# STM32H73x register map
File version: 1.0
CPU: CM7 r0p1, little endian, MPU, FPU, 4 interrupt priority bits
Registers are 32-bit, read-write, reset 0x0 unless marked. A register's access mark holds for its fields unless they carry their own. Offsets are from the block's base; [hi:lo] are bit positions; {n}, {i} and the like mark numbered series.

## DCMI — Digital camera interface
Base 0x48020000
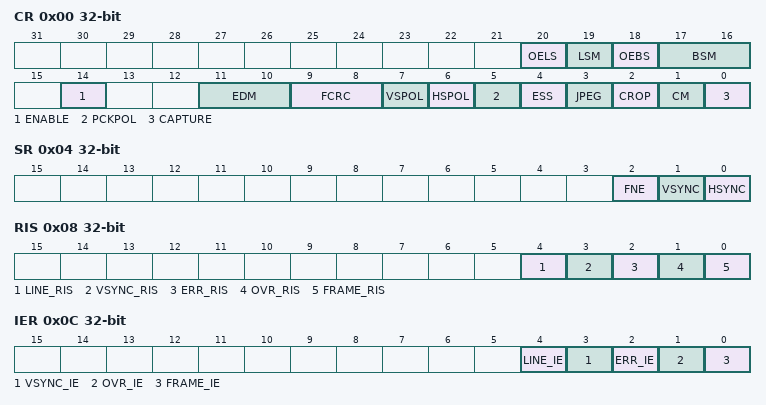
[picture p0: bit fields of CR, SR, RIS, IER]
0x00 CR — control register 1
  [20] OELS — Odd/Even Line Select (Line Select Start)
  [19] LSM — Line Select mode
  [18] OEBS — Odd/Even Byte Select (Byte Select Start)
  [17:16] BSM — Byte Select mode
  [14] ENABLE — DCMI enable
  [11:10] EDM — Extended data mode
  [9:8] FCRC — Frame capture rate control
  [7] VSPOL — Vertical synchronization polarity
  [6] HSPOL — Horizontal synchronization polarity
  [5] PCKPOL — Pixel clock polarity
  [4] ESS — Embedded synchronization select
  [3] JPEG — JPEG format
  [2] CROP — Crop feature
  [1] CM — Capture mode
  [0] CAPTURE — Capture enable
0x04 SR ro — status register
  [2] FNE — FIFO not empty
  [1] VSYNC
  [0] HSYNC
0x08 RIS ro — raw interrupt status register
  [4] LINE_RIS — Line raw interrupt status
  [3] VSYNC_RIS — VSYNC raw interrupt status
  [2] ERR_RIS — Synchronization error raw interrupt status
  [1] OVR_RIS — Overrun raw interrupt status
  [0] FRAME_RIS — Capture complete raw interrupt status
0x0C IER — interrupt enable register
  [4] LINE_IE — Line interrupt enable
  [3] VSYNC_IE — VSYNC interrupt enable
  [2] ERR_IE — Synchronization error interrupt enable
  [1] OVR_IE — Overrun interrupt enable
  [0] FRAME_IE — Capture complete interrupt enable
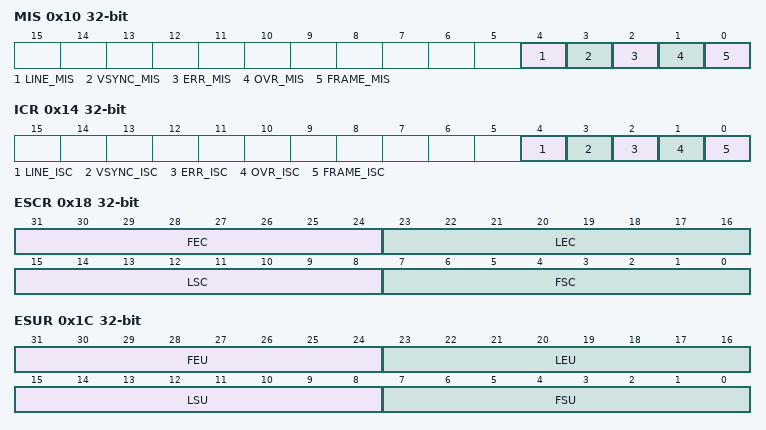
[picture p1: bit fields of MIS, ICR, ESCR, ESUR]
0x10 MIS ro — masked interrupt status register
  [4] LINE_MIS — Line masked interrupt status
  [3] VSYNC_MIS — VSYNC masked interrupt status
  [2] ERR_MIS — Synchronization error masked interrupt status
  [1] OVR_MIS — Overrun masked interrupt status
  [0] FRAME_MIS — Capture complete masked interrupt status
0x14 ICR wo — interrupt clear register
  [4] LINE_ISC — line interrupt status clear
  [3] VSYNC_ISC — Vertical synch interrupt status clear
  [2] ERR_ISC — Synchronization error interrupt status clear
  [1] OVR_ISC — Overrun interrupt status clear
  [0] FRAME_ISC — Capture complete interrupt status clear
0x18 ESCR — embedded synchronization code register
  [31:24] FEC — Frame end delimiter code
  [23:16] LEC — Line end delimiter code
  [15:8] LSC — Line start delimiter code
  [7:0] FSC — Frame start delimiter code
0x1C ESUR — embedded synchronization unmask register
  [31:24] FEU — Frame end delimiter unmask
  [23:16] LEU — Line end delimiter unmask
  [15:8] LSU — Line start delimiter unmask
  [7:0] FSU — Frame start delimiter unmask
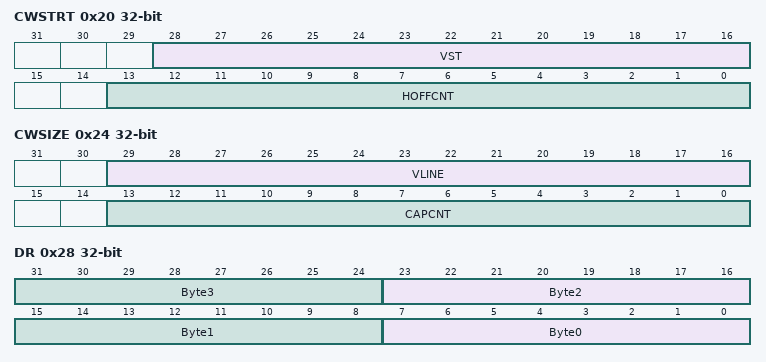
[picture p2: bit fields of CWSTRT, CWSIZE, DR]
0x20 CWSTRT — crop window start
  [28:16] VST — Vertical start line count
  [13:0] HOFFCNT — Horizontal offset count
0x24 CWSIZE — crop window size
  [29:16] VLINE — Vertical line count
  [13:0] CAPCNT — Capture count
0x28 DR ro — data register
  [8n+7:8n] Byte{n} (n=0..3) — Data byte {n}

## OTG1_HS_PWRCLK — USB 1 on the go high speed
Base 0x40040E00
Same registers: OTG2_HS_PWRCLK 0x40080E00
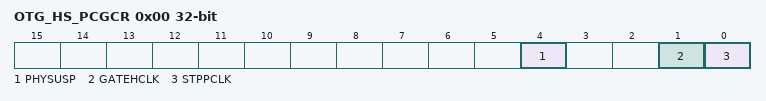
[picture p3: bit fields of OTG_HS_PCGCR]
0x00 OTG_HS_PCGCR — Power and clock gating control register
  [4] PHYSUSP — PHY suspended
  [1] GATEHCLK
  [0] STPPCLK — Stop PHY clock

## TIM16 — General-purpose-timers
Base 0x40014400
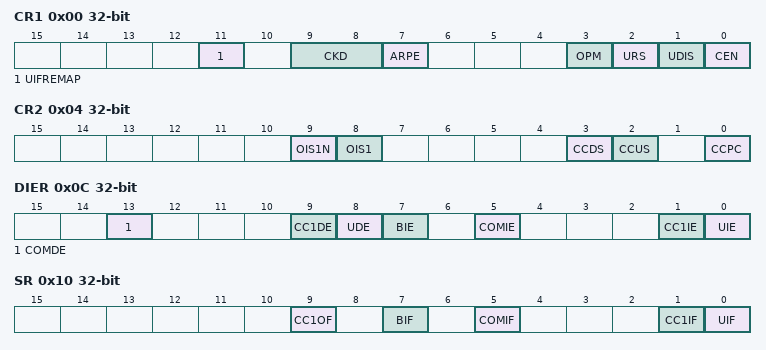
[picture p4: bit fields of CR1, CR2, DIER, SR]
0x00 CR1 — control register 1
  [11] UIFREMAP — UIF status bit remapping
  [9:8] CKD — Clock division
  [7] ARPE — Auto-reload preload enable
  [3] OPM — One-pulse mode
  [2] URS — Update request source
  [1] UDIS — Update disable
  [0] CEN — Counter enable
0x04 CR2 — control register 2
  [9] OIS1N — Output Idle state 1
  [8] OIS1 — Output Idle state 1
  [3] CCDS — Capture/compare DMA selection
  [2] CCUS — Capture/compare control update selection
  [0] CCPC — Capture/compare preloaded control
0x0C DIER — DMA/Interrupt enable register
  [13] COMDE — COM DMA request enable
  [9] CC1DE — Capture/Compare 1 DMA request enable
  [8] UDE — Update DMA request enable
  [7] BIE — Break interrupt enable
  [5] COMIE — COM interrupt enable
  [1] CC1IE — Capture/Compare 1 interrupt enable
  [0] UIE — Update interrupt enable
0x10 SR — status register
  [9] CC1OF — Capture/Compare 1 overcapture flag
  [7] BIF — Break interrupt flag
  [5] COMIF — COM interrupt flag
  [1] CC1IF — Capture/compare 1 interrupt flag
  [0] UIF — Update interrupt flag
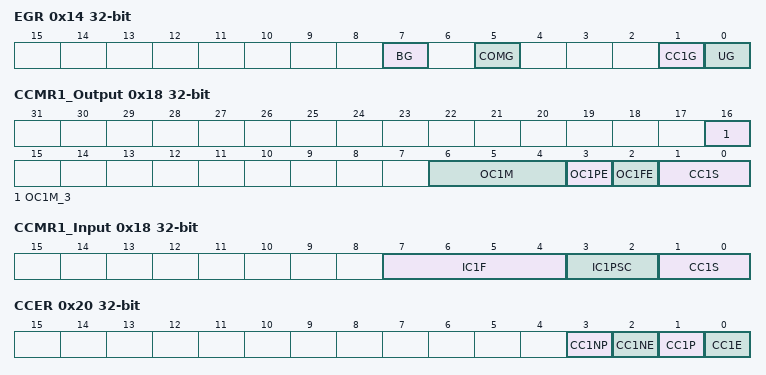
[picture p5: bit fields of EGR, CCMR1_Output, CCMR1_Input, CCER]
0x14 EGR wo — event generation register
  [7] BG — Break generation
  [5] COMG — Capture/Compare control update generation
  [1] CC1G — Capture/compare 1 generation
  [0] UG — Update generation
0x18 CCMR1_Output — capture/compare mode register (output mode)
  [16] OC1M_3 — Output Compare 1 mode
  [6:4] OC1M — Output Compare 1 mode
  [3] OC1PE — Output Compare 1 preload enable
  [2] OC1FE — Output Compare 1 fast enable
  [1:0] CC1S — Capture/Compare 1 selection
0x18 CCMR1_Input (alternate view of CCMR1_Output) — capture/compare mode register 1 (input mode)
  [7:4] IC1F — Input capture 1 filter
  [3:2] IC1PSC — Input capture 1 prescaler
  [1:0] CC1S — Capture/Compare 1 selection
0x20 CCER — capture/compare enable register
  [3] CC1NP — Capture/Compare 1 output Polarity
  [2] CC1NE — Capture/Compare 1 complementary output enable
  [1] CC1P — Capture/Compare 1 output Polarity
  [0] CC1E — Capture/Compare 1 output enable
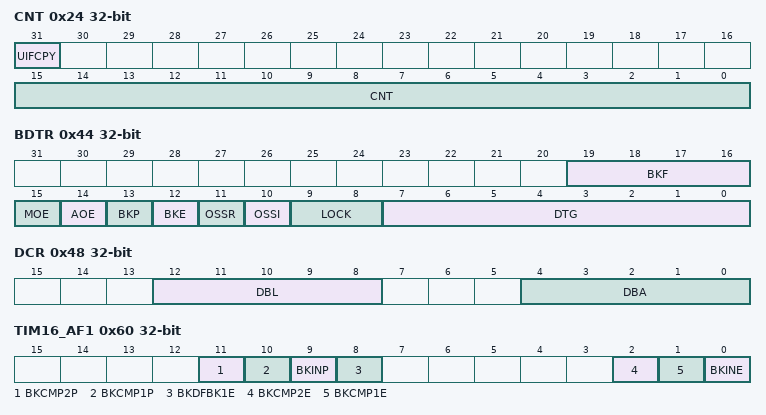
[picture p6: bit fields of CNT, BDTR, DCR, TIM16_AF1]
0x24 CNT access per field — counter
  [31] UIFCPY ro — UIF Copy
  [15:0] CNT rw — counter value
0x28 PSC — prescaler
  [15:0] PSC — Prescaler value
0x2C ARR — auto-reload register
  [15:0] ARR — Auto-reload value
0x30 RCR — repetition counter register
  [7:0] REP — Repetition counter value
0x34 CCR1 — capture/compare register 1
  [15:0] CCR1 — Capture/Compare 1 value
0x44 BDTR — break and dead-time register
  [19:16] BKF — Break filter
  [15] MOE — Main output enable
  [14] AOE — Automatic output enable
  [13] BKP — Break polarity
  [12] BKE — Break enable
  [11] OSSR — Off-state selection for Run mode
  [10] OSSI — Off-state selection for Idle mode
  [9:8] LOCK — Lock configuration
  [7:0] DTG — Dead-time generator setup
0x48 DCR — DMA control register
  [12:8] DBL — DMA burst length
  [4:0] DBA — DMA base address
0x4C DMAR — DMA address for full transfer
  [15:0] DMAB — DMA register for burst accesses
0x60 TIM16_AF1 — TIM16 alternate function register 1
  [11] BKCMP2P — BRK COMP2 input polarity
  [10] BKCMP1P — BRK COMP1 input polarity
  [9] BKINP — BRK BKIN input polarity
  [8] BKDFBK1E — BRK dfsdm1_break[1] enable
  [2] BKCMP2E — BRK COMP2 enable
  [1] BKCMP1E — BRK COMP1 enable
  [0] BKINE — BRK BKIN input enable
0x68 TIM16_TISEL — TIM16 input selection register
  [3:0] TI1SEL — selects TI1[0] to TI1[15] input

## TIM17 — General-purpose-timers
Base 0x40014800
Registers as TIM16 (with TIM16 read as TIM17).
